# STM32F40x register map
File version: 1.5
Registers are 32-bit, read-write, reset 0x0 unless marked. A register's access mark holds for its fields unless they carry their own. Offsets are from the block's base; [hi:lo] are bit positions; {n}, {i} and the like mark numbered series; 'fields as' and 'values as' point back to an identical list.

## OTG_FS_HOST（USB_OTG_FS_主机寄存器） — USB OTG FS 主机寄存器（best-effort） | USB on the go full speed
Base 0x50000400
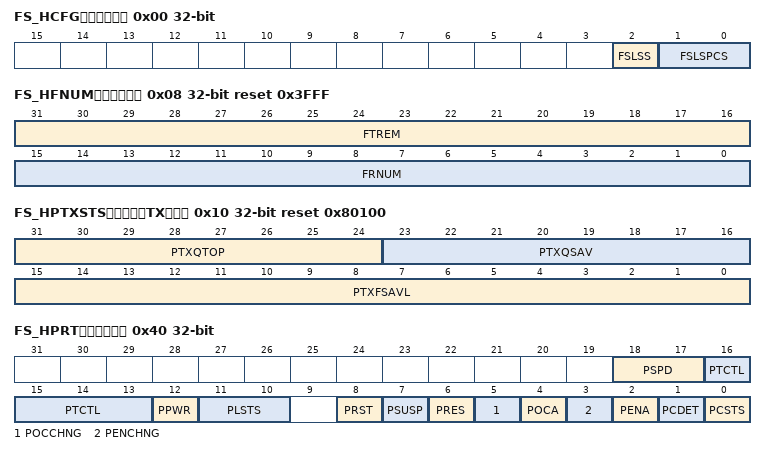
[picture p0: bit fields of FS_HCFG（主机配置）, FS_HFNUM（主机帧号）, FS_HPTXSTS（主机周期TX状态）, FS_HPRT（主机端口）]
0x00 FS_HCFG（主机配置） access per field — 主机配置 | OTG_FS host configuration register (OTG_FS_HCFG)
  [2] FSLSS ro — FS- and LS-only support
  [1:0] FSLSPCS rw — FS/LS PHY clock select
0x04 HFIR（主机帧间隔） reset 0xEA60 — 主机帧间隔 | OTG_FS Host frame interval register
  [15:0] FRIVL — Frame interval
0x08 FS_HFNUM（主机帧号） ro reset 0x3FFF — 主机帧编号 | OTG_FS host frame number/frame time remaining register (OTG_FS_HFNUM)
  [31:16] FTREM — Frame time remaining
  [15:0] FRNUM — Frame number
0x10 FS_HPTXSTS（主机周期TX状态） access per field reset 0x80100 — 主机周期发送状态 | OTG_FS_Host periodic transmit FIFO/queue status register (OTG_FS_HPTXSTS)
  [31:24] PTXQTOP ro — Top of the periodic transmit request queue
  [23:16] PTXQSAV ro — Periodic transmit request queue space available
  [15:0] PTXFSAVL rw — Periodic transmit data FIFO space available
0x14 HAINT（主机通道中断） ro — 主机所有通道中断 | OTG_FS Host all channels interrupt register
  [15:0] HAINT — Channel interrupts
0x18 HAINTMSK（主机通道中断屏蔽） — 主机通道中断屏蔽 | OTG_FS host all channels interrupt mask register
  [15:0] HAINTM — Channel interrupt mask
0x40 FS_HPRT（主机端口） access per field — 主机端口 | OTG_FS host port control and status register (OTG_FS_HPRT)
  [18:17] PSPD ro — Port speed
  [16:13] PTCTL rw — Port test control
  [12] PPWR rw — Port power
  [11:10] PLSTS ro — Port line status
  [8] PRST rw — Port reset
  [7] PSUSP rw — Port suspend
  [6] PRES rw — Port resume
  [5] POCCHNG rw — Port overcurrent change
  [4] POCA ro — Port overcurrent active
  [3] PENCHNG rw — Port enable/disable change
  [2] PENA rw — Port enable
  [1] PCDET rw — Port connect detected
  [0] PCSTS ro — Port connect status
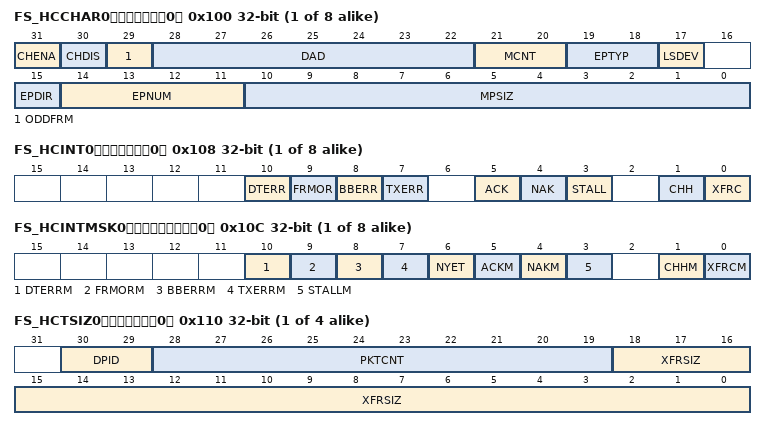
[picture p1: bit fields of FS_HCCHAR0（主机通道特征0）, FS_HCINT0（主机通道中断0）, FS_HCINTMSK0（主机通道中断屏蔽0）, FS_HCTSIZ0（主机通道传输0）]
{0x100+0x20*i} FS_HCCHAR{i}（主机通道特征{i}） (i=0..7) — USB OTG FS 主机通道特征{i} | OTG_FS host channel-{i} characteristics register (OTG_FS_HCCHAR{i})
  [31] CHENA — Channel enable
  [30] CHDIS — Channel disable
  [29] ODDFRM — Odd frame
  [28:22] DAD — Device address
  [21:20] MCNT — Multicount
  [19:18] EPTYP — Endpoint type
  [17] LSDEV — Low-speed device
  [15] EPDIR — Endpoint direction
  [14:11] EPNUM — Endpoint number
  [10:0] MPSIZ — Maximum packet size
{0x108+0x20*i} FS_HCINT{i}（主机通道中断{i}） (i=0..7) — USB OTG FS 主机通道中断{i} | OTG_FS host channel-{i} interrupt register (OTG_FS_HCINT{i})
  [10] DTERR — Data toggle error
  [9] FRMOR — Frame overrun
  [8] BBERR — Babble error
  [7] TXERR — Transaction error
  [5] ACK — ACK response received/transmitted interrupt
  [4] NAK — NAK response received interrupt
  [3] STALL — STALL response received interrupt
  [1] CHH — Channel halted
  [0] XFRC — Transfer completed
{0x10C+0x20*i} FS_HCINTMSK{i}（主机通道中断屏蔽{i}） (i=0..7) — USB OTG FS 主机通道中断屏蔽{i} | OTG_FS host channel-{i} mask register (OTG_FS_HCINTMSK{i})
  [10] DTERRM — Data toggle error mask
  [9] FRMORM — Frame overrun mask
  [8] BBERRM — Babble error mask
  [7] TXERRM — Transaction error mask
  [6] NYET — response received interrupt mask
  [5] ACKM — ACK response received/transmitted interrupt mask
  [4] NAKM — NAK response received interrupt mask
  [3] STALLM — STALL response received interrupt mask
  [1] CHHM — Channel halted mask
  [0] XFRCM — Transfer completed mask
{0x110+0x20*i} FS_HCTSIZ{i}（主机通道传输{i}） (i=0..3) — USB OTG FS 主机通道传输{i} | OTG_FS host channel-{i} transfer size register
  [30:29] DPID — Data PID
  [28:19] PKTCNT — Packet count
  [18:0] XFRSIZ — Transfer size
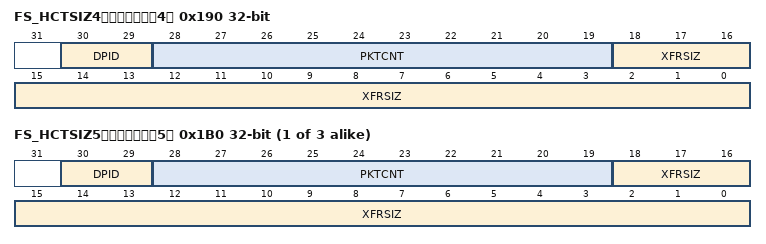
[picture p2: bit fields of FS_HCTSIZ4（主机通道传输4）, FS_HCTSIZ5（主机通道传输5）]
0x190 FS_HCTSIZ4（主机通道传输4） — USB OTG FS 主机通道传输4 | OTG_FS host channel-x transfer size register
  fields as FS_HCTSIZ0（主机通道传输0）
{0x110+0x20*i} FS_HCTSIZ{i}（主机通道传输{i}） (i=5..7) — USB OTG FS 主机通道传输{i} | OTG_FS host channel-{i} transfer size register
  fields as FS_HCTSIZ0（主机通道传输0）

## OTG_FS_PWRCLK（USB_OTG_FS_电源时钟寄存器） — USB OTG FS 电源时钟寄存器（best-effort） | USB on the go full speed
Base 0x50000E00
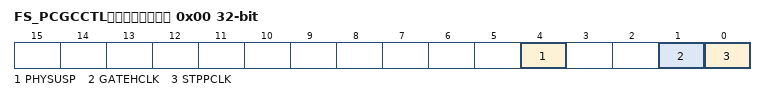
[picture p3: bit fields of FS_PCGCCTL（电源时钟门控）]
0x00 FS_PCGCCTL（电源时钟门控） — 电源与时钟门控 | OTG_FS power and clock gating control register
  [4] PHYSUSP — PHY Suspended
  [1] GATEHCLK
  [0] STPPCLK — Stop PHY clock
